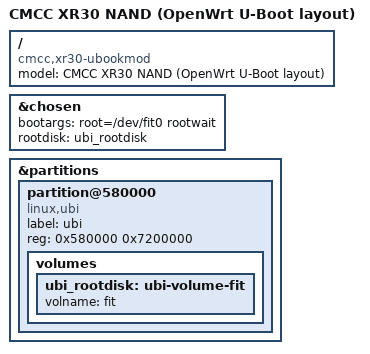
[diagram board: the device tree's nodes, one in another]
// SPDX-License-Identifier: GPL-2.0-or-later OR MIT
/*
 * Copyright (C) 2023 Tianling Shen <cnsztl@immortalwrt.org>
 */

/dts-v1/;
#include "mt7981b-cmcc-xr30.dtsi"

/ {
	model = "CMCC XR30 NAND (OpenWrt U-Boot layout)";
	compatible = "cmcc,xr30-ubookmod", "mediatek,mt7981";
};

&chosen {
	bootargs = "root=/dev/fit0 rootwait";
	rootdisk = <&ubi_rootdisk>;
};

&partitions {
	partition@580000 {
		compatible = "linux,ubi";
		label = "ubi";
		reg = <0x580000 0x7200000>;

		volumes {
			ubi_rootdisk: ubi-volume-fit {
				volname = "fit";
			};
		};
	};
};
